# EFR32BG21A010F1024IM32 register map
Vendor: Silicon Labs; Series: EFR32; File version: B
Registers are 32-bit, read-write, reset 0x0 unless marked. A register's access mark holds for its fields unless they carry their own. Offsets are from the block's base; [hi:lo] are bit positions; 'fields as' and 'values as' point back to an identical list.

## EMU_S — EMU_S Registers
Base 0x40004000
Same registers: EMU_NS 0x50004000
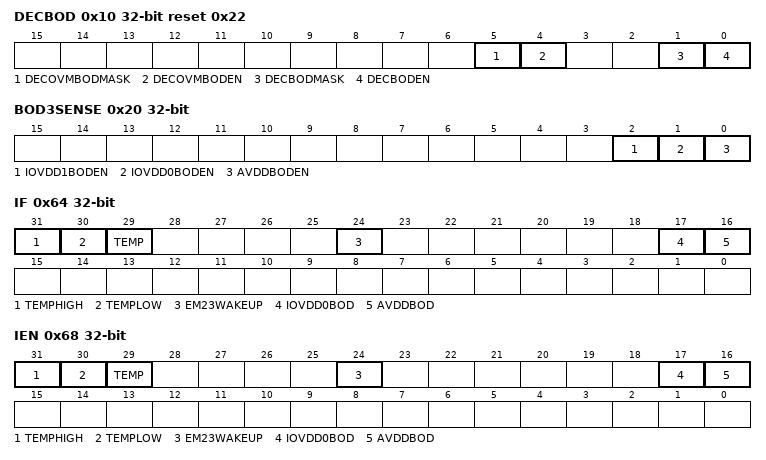
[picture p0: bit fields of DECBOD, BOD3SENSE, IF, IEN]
0x10 DECBOD reset 0x22
  [5] DECOVMBODMASK — Over Voltage Monitor Mask
  [4] DECOVMBODEN — Over Voltage Monitor enable
  [1] DECBODMASK
  [0] DECBODEN — DECBOD enable
0x20 BOD3SENSE
  [2] IOVDD1BODEN — VDDIO1 BOD enable
  [1] IOVDD0BODEN — VDDIO0 BOD enable
  [0] AVDDBODEN — AVDD BOD enable
0x60 LOCK wo reset 0xADE8
  [15:0] LOCKKEY
    0xADE8=UNLOCK (Unlock EMU register)
0x64 IF
  [31] TEMPHIGH — Temperature high Interrupt flag
  [30] TEMPLOW — Temperature low Interrupt flag
  [29] TEMP — Temperature Interrupt flag
  [24] EM23WAKEUP — EM23 Wake up Interrupt flag
  [17] IOVDD0BOD — VDDIO0 BOD Interrupt flag
  [16] AVDDBOD — AVDD BOD Interrupt flag
0x68 IEN
  [31] TEMPHIGH — Temperature high Interrupt enable
  [30] TEMPLOW — Temperature low Interrupt enable
  [29] TEMP — Temperature Interrupt enable
  [24] EM23WAKEUP — EM23 Wake up Interrupt enable
  [17] IOVDD0BOD — VDDIO0 BOD Interrupt enable
  [16] AVDDBOD — AVDD BOD Interrupt enable
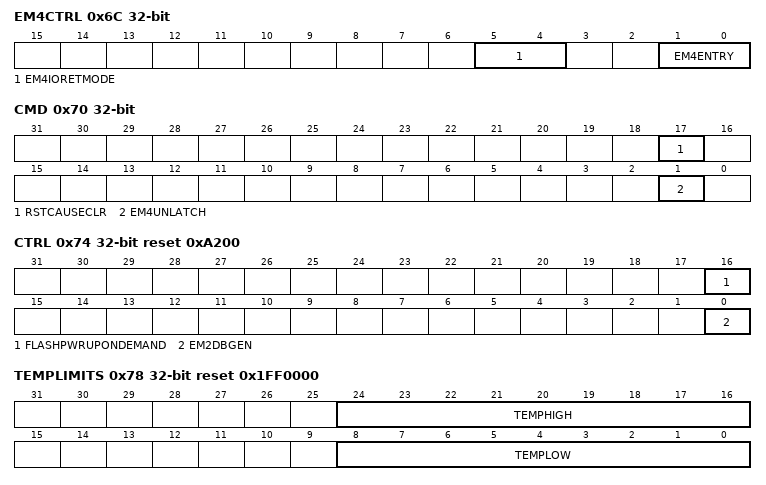
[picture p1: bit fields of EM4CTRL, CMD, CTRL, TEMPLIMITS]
0x6C EM4CTRL
  [5:4] EM4IORETMODE — EM4 IO retention mode
    0=DISABLE (No Retention: Pads enter reset state when entering EM4); 1=EM4EXIT (Retention through EM4: Pads enter reset state when exiting EM4); 2=SWUNLATCH (Retention through EM4 and Wakeup: software sets EM4UNLATCH in EMU_CMD register to remove retention)
  [1:0] EM4ENTRY — EM4 entry request
0x70 CMD wo
  [17] RSTCAUSECLR — Reset Cause Clear
  [1] EM4UNLATCH
0x74 CTRL reset 0xA200
  [16] FLASHPWRUPONDEMAND — Enable flash on demand wakeup
  [0] EM2DBGEN — Enable debugging in EM2
0x78 TEMPLIMITS reset 0x1FF0000
  [24:16] TEMPHIGH — Temp High limit
  [8:0] TEMPLOW — Temp Low limit
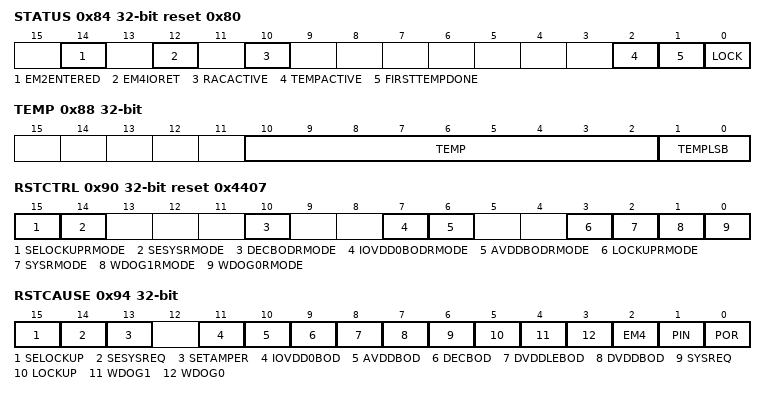
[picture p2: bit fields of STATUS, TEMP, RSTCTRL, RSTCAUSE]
0x84 STATUS ro reset 0x80
  [14] EM2ENTERED
  [12] EM4IORET — EM4 IO retention status
  [10] RACACTIVE
  [2] TEMPACTIVE
  [1] FIRSTTEMPDONE
  [0] LOCK — Lock status
    0=UNLOCKED (All EMU lockable registers are unlocked.); 1=LOCKED (All EMU lockable registers are locked.)
0x88 TEMP ro
  [10:2] TEMP — Temperature measured
  [1:0] TEMPLSB — Temperature measured decimal part
0x90 RSTCTRL reset 0x4407
  [15] SELOCKUPRMODE — Enable SE Lockup reset
    0=DISABLED (Reset request is blocked); 1=ENABLED (The entire device is reset except some EMU registers)
  [14] SESYSRMODE — Enable SE System reset
    values as SELOCKUPRMODE
  [10] DECBODRMODE — Enable DECBOD reset
    0=DISABLED (Reset request is blocked); 1=ENABLED (The entire device is reset)
  [7] IOVDD0BODRMODE — Enable VDDIO0 BOD reset
    values as SELOCKUPRMODE
  [6] AVDDBODRMODE — Enable AVDD BOD reset
    0=DISABLED (Reset Request is block); 1=ENABLED (The entire device is reset except some EMU registers)
  [3] LOCKUPRMODE — Enable M33 Lockup reset
    0=DISABLED (Reset Request is Block); 1=ENABLED (The entire device is reset except some EMU registers)
  [2] SYSRMODE — Enable M33 System reset
    0=DISABLED (Reset request is blocked); 1=ENABLED (Device is reset except some EMU registers)
  [1] WDOG1RMODE — Enable WDOG1 reset
    values as SELOCKUPRMODE
  [0] WDOG0RMODE — Enable WDOG0 reset
    values as SELOCKUPRMODE
0x94 RSTCAUSE ro
  [15] SELOCKUP — SE Lockup Reset
  [14] SESYSREQ — SE System Reset
  [13] SETAMPER — SE Tamper event Reset
  [11] IOVDD0BOD — LEBOD2 Reset
  [10] AVDDBOD — LEBOD1 Reset
  [9] DECBOD — LVBOD Reset
  [8] DVDDLEBOD — LEBOD Reset
  [7] DVDDBOD — HVBOD Reset
  [6] SYSREQ — M33 Core Sys Reset
  [5] LOCKUP — M33 Core Lockup Reset
  [4] WDOG1 — Watchdog 1 Reset
  [3] WDOG0 — Watchdog 0 Reset
  [2] EM4 — EM4 Wakeup Reset
  [1] PIN — Pin Reset
  [0] POR — Power On Reset
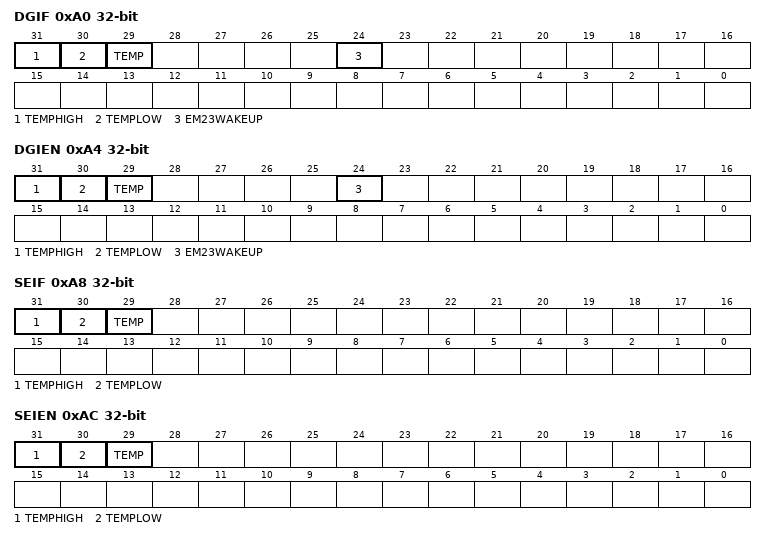
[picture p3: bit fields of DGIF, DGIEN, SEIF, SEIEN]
0xA0 DGIF
  [31] TEMPHIGH — Temperature high Interrupt flag
  [30] TEMPLOW — Temperature low Interrupt flag
  [29] TEMP — Temperature Interrupt flag
  [24] EM23WAKEUP — EM23 Wake up Interrupt flag
0xA4 DGIEN
  [31] TEMPHIGH — Temperature high Interrupt enable
  [30] TEMPLOW — Temperature low Interrupt enable
  [29] TEMP — Temperature Interrupt enable
  [24] EM23WAKEUP — EM23 Wake up Interrupt enable
0xA8 SEIF
  [31] TEMPHIGH — Temperature low Interrupt flag
  [30] TEMPLOW — Temperature Interrupt flag
  [29] TEMP — Temperature Interrupt flag
0xAC SEIEN
  [31] TEMPHIGH — Temperature high Interrupt enable
  [30] TEMPLOW — Temperature low Interrupt enable
  [29] TEMP — Temperature Interrupt enable
